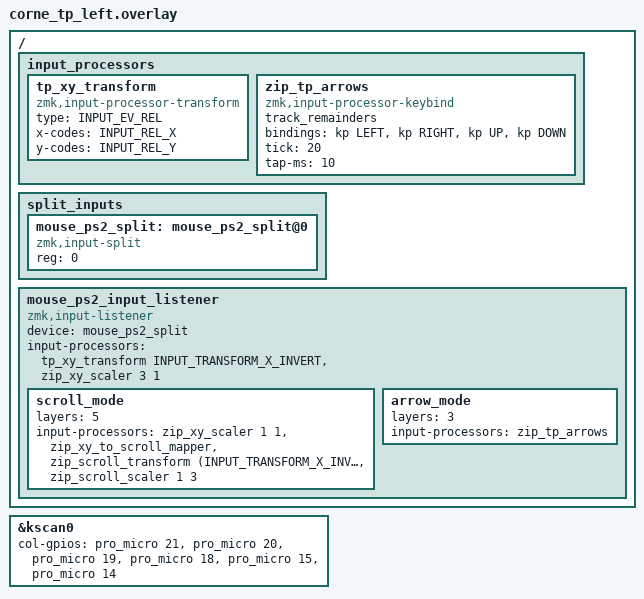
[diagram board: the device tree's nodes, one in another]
/*
 * Copyright (c) 2020 Pete Johanson
 *
 * SPDX-License-Identifier: MIT
 */

#include "corne_tp.dtsi"
#include <dt-bindings/zmk/input_transform.h>
#include <zephyr/dt-bindings/input/input-event-codes.h>
#include <input/processors.dtsi>
#include <input/processors/zmk-input-processor-keybind.dtsi>
#include <dt-bindings/zmk/keys.h>

/ {
    input_processors {
        tp_xy_transform: tp_xy_transform {
            compatible = "zmk,input-processor-transform";
            #input-processor-cells = <1>;
            type = <INPUT_EV_REL>;
            x-codes = <INPUT_REL_X>;
            y-codes = <INPUT_REL_Y>;
        };

        zip_tp_arrows: zip_tp_arrows {
            compatible = "zmk,input-processor-keybind";
            #input-processor-cells = <0>;
            track_remainders;
            bindings = <&kp LEFT>,
                       <&kp RIGHT>,
                       <&kp UP>,
                       <&kp DOWN>;
            tick = <20>;
            tap-ms = <10>;
        };
    };

    split_inputs {
        #address-cells = <1>;
        #size-cells = <0>;

        mouse_ps2_split: mouse_ps2_split@0 {
            compatible = "zmk,input-split";
            reg = <0>;
        };
    };

    mouse_ps2_input_listener: mouse_ps2_input_listener {
        compatible = "zmk,input-listener";
        status = "okay";

        device = <&mouse_ps2_split>;
        input-processors = <&tp_xy_transform INPUT_TRANSFORM_X_INVERT &zip_xy_scaler 3 1>;

        /* Scroll mode: trackpoint becomes scroll wheel on FUN layer */
        scroll_mode {
            layers = <5>;
            input-processors = <&zip_xy_scaler 1 1 &zip_xy_to_scroll_mapper &zip_scroll_transform (INPUT_TRANSFORM_X_INVERT | INPUT_TRANSFORM_Y_INVERT) &zip_scroll_scaler 1 3>;
        };

        /* Arrow mode: trackpoint emits arrow keys on SYM layer */
        arrow_mode {
            layers = <3>;
            input-processors = <&zip_tp_arrows>;
        };
    };
};

&kscan0 {
    col-gpios
        = <&pro_micro 21 GPIO_ACTIVE_HIGH>
        , <&pro_micro 20 GPIO_ACTIVE_HIGH>
        , <&pro_micro 19 GPIO_ACTIVE_HIGH>
        , <&pro_micro 18 GPIO_ACTIVE_HIGH>
        , <&pro_micro 15 GPIO_ACTIVE_HIGH>
        , <&pro_micro 14 GPIO_ACTIVE_HIGH>
        ;
};
